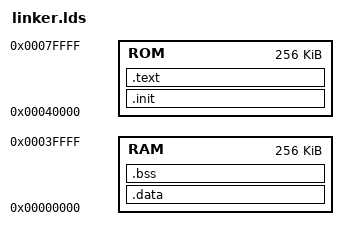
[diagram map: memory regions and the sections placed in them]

ENTRY(_start16)

MEMORY
{
        RAM : ORIGIN = 0x00000000, LENGTH = 256k
        ROM : ORIGIN = 0x00040000, LENGTH = 256k
}

SECTIONS
{
        /**********************************************************************
         *                                                                    *
         **********************************************************************/
        .init : AT(ORIGIN(ROM))
        {
                *(.init16)
                . = ALIGN(0x10);
        } > ROM
        /**********************************************************************
         *                                                                    *
         **********************************************************************/
        .text ALIGN(0x20) :
        {
                _stext = .;
                . = ALIGN(0x10);
                *(.startup)
                *(.text)
                *(.text.*)
                *(.rodata)
                *(.rodata.*)
                . = ALIGN(0x4);
                PROVIDE(_debug_flag = .);
                BYTE(0x00);
                . = ALIGN(0x10);
                _etext = .;
        } > ROM
        /**********************************************************************
         *                                                                    *
         **********************************************************************/
        .data : AT(_etext)
        {
                _sdata = .;
                . = ALIGN(0x10);
                *(.data)
                *(.data.*)
                . = ALIGN(0x10);
                _edata = .;
        } > RAM
        /**********************************************************************
         *                                                                    *
         **********************************************************************/
        .bss ADDR(.data) + SIZEOF(.data) (NOLOAD) :
        {
                . = ALIGN(0x10);
                _sbss = .;
                *(.bss)
                *(.bss.*)
                *(COMMON)
                . = ALIGN(0x10);
                _ebss = .;
        } > RAM
        /**********************************************************************
         *                                                                    *
         **********************************************************************/
        .debug_info     0 : { *(.debug_info) }
        .debug_abbrev   0 : { *(.debug_abbrev) }
        .debug_aranges  0 : { *(.debug_aranges) }
        .debug_frame    0 : { *(.debug_frame) }
        .debug_line     0 : { *(.debug_line) }
        .debug_line_str 0 : { *(.debug_line_str) }
        .debug_loclists 0 : { *(.debug_loclists) }
        .debug_macro    0 : { *(.debug_macro) }
        .debug_names    0 : { *(.debug_names) }
        .debug_rnglists 0 : { *(.debug_rnglists) }
        .debug_str      0 : { *(.debug_str) }
        /**********************************************************************
         *                                                                    *
         **********************************************************************/
        /DISCARD/ :
        {
                *(*)
        }
}

